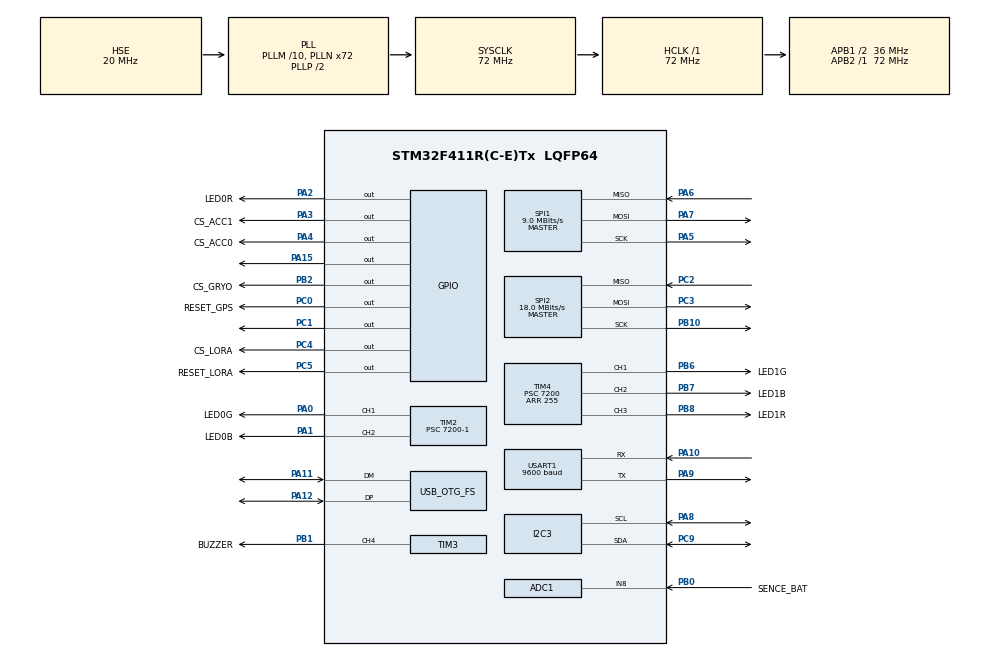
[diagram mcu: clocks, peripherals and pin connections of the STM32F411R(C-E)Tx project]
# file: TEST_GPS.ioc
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ADC1.Channel-0\#ChannelRegularConversion=ADC_CHANNEL_8
ADC1.NbrOfConversionFlag=1
ADC1.Rank-0\#ChannelRegularConversion=1
ADC1.SamplingTime-0\#ChannelRegularConversion=ADC_SAMPLETIME_3CYCLES
ADC1.master=1
Mcu.Family=STM32F4
Mcu.Name=STM32F411R(C-E)Tx
Mcu.Package=LQFP64
NVIC.OTG_FS_IRQn=true\:0\:0\:false\:false\:true\:false\:true\:true
NVIC.PriorityGroup=NVIC_PRIORITYGROUP_4
PA0-WKUP.GPIO_Label=LED0G
PA0-WKUP.Signal=S_TIM2_CH1_ETR
PA1.GPIO_Label=LED0B
PA1.Signal=S_TIM2_CH2
PA10.Mode=Asynchronous
PA10.Signal=USART1_RX
PA11.Mode=Device_Only
PA11.Signal=USB_OTG_FS_DM
PA12.Mode=Device_Only
PA12.Signal=USB_OTG_FS_DP
PA13.Mode=Serial_Wire
PA13.Signal=SYS_JTMS-SWDIO
PA14.Mode=Serial_Wire
PA14.Signal=SYS_JTCK-SWCLK
PA15.Signal=GPIO_Output
PA2.GPIO_Label=LED0R
PA2.Signal=GPIO_Output
PA3.GPIO_Label=CS_ACC1
PA3.Signal=GPIO_Output
PA4.GPIO_Label=CS_ACC0
PA4.Signal=GPIO_Output
PA5.Mode=Full_Duplex_Master
PA5.Signal=SPI1_SCK
PA6.Mode=Full_Duplex_Master
PA6.Signal=SPI1_MISO
PA7.Mode=Full_Duplex_Master
PA7.Signal=SPI1_MOSI
PA8.Mode=I2C
PA8.Signal=I2C3_SCL
PA9.Mode=Asynchronous
PA9.Signal=USART1_TX
PB0.GPIO_Label=SENCE_BAT
PB0.Signal=ADCx_IN8
PB1.GPIO_Label=BUZZER
PB1.Signal=S_TIM3_CH4
PB10.Mode=Full_Duplex_Master
PB10.Signal=SPI2_SCK
PB2.GPIO_Label=CS_GRYO
PB2.Signal=GPIO_Output
PB6.GPIO_Label=LED1G
PB6.Signal=S_TIM4_CH1
PB7.GPIO_Label=LED1B
PB7.Signal=S_TIM4_CH2
PB8.GPIO_Label=LED1R
PB8.Signal=S_TIM4_CH3
PC0.GPIO_Label=RESET_GPS
PC0.Signal=GPIO_Output
PC1.Signal=GPIO_Output
PC14-OSC32_IN.Mode=LSE-External-Oscillator
PC14-OSC32_IN.Signal=RCC_OSC32_IN
PC15-OSC32_OUT.Mode=LSE-External-Oscillator
PC15-OSC32_OUT.Signal=RCC_OSC32_OUT
PC2.Mode=Full_Duplex_Master
PC2.Signal=SPI2_MISO
PC3.Mode=Full_Duplex_Master
PC3.Signal=SPI2_MOSI
PC4.GPIO_Label=CS_LORA
PC4.Signal=GPIO_Output
PC5.GPIO_Label=RESET_LORA
PC5.Signal=GPIO_Output
PC9.Mode=I2C
PC9.Signal=I2C3_SDA
PH0\ -\ OSC_IN.Mode=HSE-External-Oscillator
PH0\ -\ OSC_IN.Signal=RCC_OSC_IN
PH1\ -\ OSC_OUT.Mode=HSE-External-Oscillator
PH1\ -\ OSC_OUT.Signal=RCC_OSC_OUT
ProjectManager.HeapSize=0x200
ProjectManager.StackSize=0x400
ProjectManager.TargetToolchain=CMake
RCC.48MHZClocksFreq_Value=48000000
RCC.AHBFreq_Value=72000000
RCC.APB1CLKDivider=RCC_HCLK_DIV2
RCC.APB1Freq_Value=36000000
RCC.APB1TimFreq_Value=72000000
RCC.APB2Freq_Value=72000000
RCC.APB2TimFreq_Value=72000000
RCC.CortexFreq_Value=72000000
RCC.HCLKFreq_Value=72000000
RCC.HSE_VALUE=20000000
RCC.HSI_VALUE=16000000
RCC.PLLM=10
RCC.PLLN=72
RCC.PLLQ=3
RCC.SYSCLKFreq_VALUE=72000000
RCC.SYSCLKSource=RCC_SYSCLKSOURCE_PLLCLK
RCC.VCOOutputFreq_Value=144000000
SH.ADCx_IN8.0=ADC1_IN8,IN8
SH.S_TIM2_CH1_ETR.0=TIM2_CH1,PWM Generation1 CH1
SH.S_TIM2_CH2.0=TIM2_CH2,PWM Generation2 CH2
SH.S_TIM3_CH4.0=TIM3_CH4,PWM Generation4 CH4
SH.S_TIM4_CH1.0=TIM4_CH1,PWM Generation1 CH1
SH.S_TIM4_CH2.0=TIM4_CH2,PWM Generation2 CH2
SH.S_TIM4_CH3.0=TIM4_CH3,Output Compare3 CH3
SPI1.BaudRatePrescaler=SPI_BAUDRATEPRESCALER_8
SPI1.CalculateBaudRate=9.0 MBits/s
SPI1.Direction=SPI_DIRECTION_2LINES
SPI1.Mode=SPI_MODE_MASTER
SPI1.VirtualType=VM_MASTER
SPI2.CalculateBaudRate=18.0 MBits/s
SPI2.Direction=SPI_DIRECTION_2LINES
SPI2.Mode=SPI_MODE_MASTER
SPI2.VirtualType=VM_MASTER
TIM2.Channel-PWM\ Generation1\ CH1=TIM_CHANNEL_1
TIM2.Channel-PWM\ Generation2\ CH2=TIM_CHANNEL_2
TIM2.Period=255
TIM2.Prescaler=7200-1
TIM3.Channel-PWM\ Generation4\ CH4=TIM_CHANNEL_4
TIM3.Period=255
TIM3.Prescaler=7200
TIM4.Channel-Output\ Compare3\ CH3=TIM_CHANNEL_3
TIM4.Channel-PWM\ Generation1\ CH1=TIM_CHANNEL_1
TIM4.Channel-PWM\ Generation2\ CH2=TIM_CHANNEL_2
TIM4.Period=255
TIM4.Prescaler=7200
USART1.BaudRate=9600
USART1.VirtualMode=VM_ASYNC
USB_DEVICE.CLASS_NAME_FS=CDC
USB_DEVICE.VirtualMode=Cdc
USB_DEVICE.VirtualModeFS=Cdc_FS
USB_OTG_FS.VirtualMode=Device_Only
VP_TIM2_VS_ClockSourceINT.Mode=Internal
VP_TIM4_VS_ClockSourceINT.Mode=Internal
VP_USB_DEVICE_VS_USB_DEVICE_CDC_FS.Mode=CDC_FS
board=custom

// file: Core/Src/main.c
/* USER CODE BEGIN Header */
/**
  ******************************************************************************
  * @file           : main.c
  * @brief          : Main program body
  ******************************************************************************
  * @attention
  *
  * Copyright (c) 2025 STMicroelectronics.
  * All rights reserved.
  *
  * This software is licensed under terms that can be found in the LICENSE file
  * in the root directory of this software component.
  * If no LICENSE file comes with this software, it is provided AS-IS.
  *
  ******************************************************************************
  */
/* USER CODE END Header */
#include "main.h"
#include "adc.h"
#include "i2c.h"
#include "spi.h"
#include "tim.h"
#include "usart.h"
#include "usb_device.h"
#include "gpio.h"

void SystemClock_Config(void);

int main(void)
{

  /* MCU Configuration--------------------------------------------------------*/

  /* Reset of all peripherals, Initializes the Flash interface and the Systick. */
  HAL_Init();

  /* Configure the system clock */
  SystemClock_Config();

  /* Initialize all configured peripherals */
  MX_GPIO_Init();
  MX_I2C3_Init();
  MX_SPI2_Init();
  MX_TIM2_Init();
  MX_TIM4_Init();
  MX_USART1_UART_Init();
  MX_ADC1_Init();
  MX_SPI1_Init();
  MX_TIM3_Init();
  MX_USB_DEVICE_Init();
  /* USER CODE BEGIN 2 */

  uint8_t data[256];

  HAL_GPIO_WritePin(LED0R_GPIO_Port, LED0R_Pin, GPIO_PIN_SET);

  /* USER CODE END 2 */

  /* Infinite loop */
  /* USER CODE BEGIN WHILE */
  while (1)
  {

    // HAL_UART_Receive(&huart1, data, sizeof(data), HAL_MAX_DELAY);
    // CDC_Transmit_FS(data, sizeof(data));
    // HAL_Delay(100);

    /* USER CODE END WHILE */

  }
}

void SystemClock_Config(void)
{
  RCC_OscInitTypeDef RCC_OscInitStruct = {0};
  RCC_ClkInitTypeDef RCC_ClkInitStruct = {0};

  /** Configure the main internal regulator output voltage
  */
  __HAL_RCC_PWR_CLK_ENABLE();
  __HAL_PWR_VOLTAGESCALING_CONFIG(PWR_REGULATOR_VOLTAGE_SCALE1);

  /** Initializes the RCC Oscillators according to the specified parameters
  * in the RCC_OscInitTypeDef structure.
  */
  RCC_OscInitStruct.OscillatorType = RCC_OSCILLATORTYPE_HSE;
  RCC_OscInitStruct.HSEState = RCC_HSE_ON;
  RCC_OscInitStruct.PLL.PLLState = RCC_PLL_ON;
  RCC_OscInitStruct.PLL.PLLSource = RCC_PLLSOURCE_HSE;
  RCC_OscInitStruct.PLL.PLLM = 10;
  RCC_OscInitStruct.PLL.PLLN = 72;
  RCC_OscInitStruct.PLL.PLLP = RCC_PLLP_DIV2;
  RCC_OscInitStruct.PLL.PLLQ = 3;
  if (HAL_RCC_OscConfig(&RCC_OscInitStruct) != HAL_OK)
  {
    Error_Handler();
  }

  /** Initializes the CPU, AHB and APB buses clocks
  */
  RCC_ClkInitStruct.ClockType = RCC_CLOCKTYPE_HCLK|RCC_CLOCKTYPE_SYSCLK
                              |RCC_CLOCKTYPE_PCLK1|RCC_CLOCKTYPE_PCLK2;
  RCC_ClkInitStruct.SYSCLKSource = RCC_SYSCLKSOURCE_PLLCLK;
  RCC_ClkInitStruct.AHBCLKDivider = RCC_SYSCLK_DIV1;
  RCC_ClkInitStruct.APB1CLKDivider = RCC_HCLK_DIV2;
  RCC_ClkInitStruct.APB2CLKDivider = RCC_HCLK_DIV1;

  if (HAL_RCC_ClockConfig(&RCC_ClkInitStruct, FLASH_LATENCY_2) != HAL_OK)
  {
    Error_Handler();
  }
}

void Error_Handler(void)
{
  __disable_irq();
  while (1)
  {
  }
}
